# MDR32F8 register map
Vendor: Milandr; File version: 1.0
CPU: CM4 r1p1, little endian, no MPU, no FPU, 3 interrupt priority bits
Registers are 32-bit, read-write, reset 0x0 unless marked. A register's access mark holds for its fields unless they carry their own. Offsets are from the block's base; [hi:lo] are bit positions; {n}, {i} and the like mark numbered series; 'fields as' and 'values as' point back to an identical list.

## ARINC429T — ARINC429 Transive Controller
Base 0x400A0000
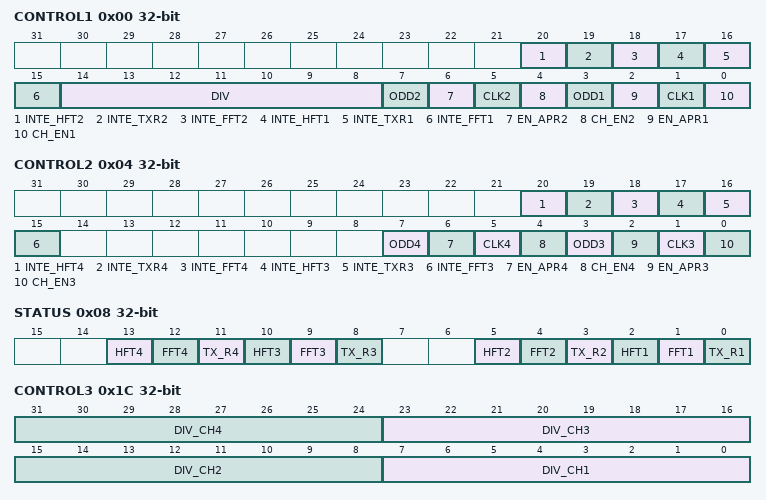
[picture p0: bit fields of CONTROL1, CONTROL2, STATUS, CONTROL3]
0x00 CONTROL1
  [20] INTE_HFT2, [19] INTE_TXR2, [18] INTE_FFT2, [17] INTE_HFT1, [16] INTE_TXR1, [15] INTE_FFT1, [14:8] DIV, [7] ODD2, [6] EN_APR2, [5] CLK2, [4] CH_EN2, [3] ODD1, [2] EN_APR1, [1] CLK1, [0] CH_EN1
0x04 CONTROL2
  [20] INTE_HFT4, [19] INTE_TXR4, [18] INTE_FFT4, [17] INTE_HFT3, [16] INTE_TXR3, [15] INTE_FFT3, [7] ODD4, [6] EN_APR4, [5] CLK4, [4] CH_EN4, [3] ODD3, [2] EN_APR3, [1] CLK3, [0] CH_EN3
0x08 STATUS
  [13] HFT4, [12] FFT4, [11] TX_R4, [10] HFT3, [9] FFT3, [8] TX_R3, [5] HFT2, [4] FFT2, [3] TX_R2, [2] HFT1, [1] FFT1, [0] TX_R1
{0x8+4i} DATA{i}_T wo (i=1..4)
0x1C CONTROL3
  [8n-1:8n-8] DIV_CH{n} (n=1..4)
0x20 CONTROL4
  [3:0] ENSYNC

## MDR_MILDAT_15530 — MIL_DATA
Base 0x400A6000
Same registers: MDR_MILDAT_15531 0x400A8000

## MDR_MIL_STD_15530 — MIL_STD_1553 interfase controller registers
Base 0x400A7000
Same registers: MDR_MIL_STD_15531 0x400A9000
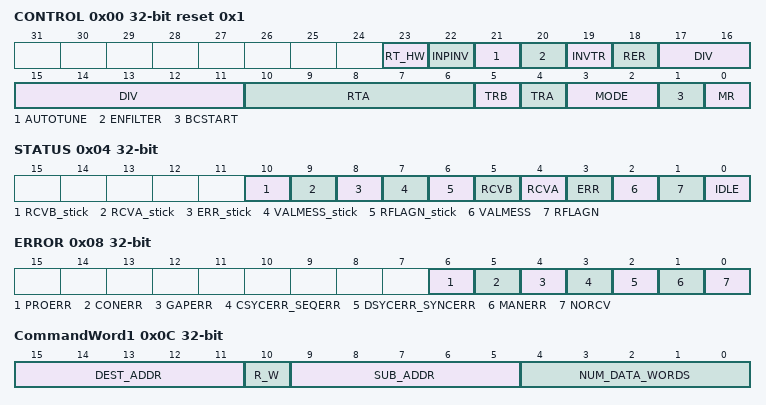
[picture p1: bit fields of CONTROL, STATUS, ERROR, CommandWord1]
0x00 CONTROL reset 0x1 — MIL_STD_1553 Register control
  [23] RT_HW, [22] INPINV, [21] AUTOTUNE, [20] ENFILTER, [19] INVTR, [18] RER, [17:11] DIV, [10:6] RTA, [5] TRB, [4] TRA, [3:2] MODE, [1] BCSTART, [0] MR
0x04 STATUS ro — MIL_STD_1553 Register status
  [10] RCVB_stick, [9] RCVA_stick, [8] ERR_stick, [7] VALMESS_stick, [6] RFLAGN_stick, [5] RCVB, [4] RCVA, [3] ERR, [2] VALMESS, [1] RFLAGN, [0] IDLE
0x08 ERROR ro — MIL_STD_1553 Register error
  [6] PROERR, [5] CONERR, [4] GAPERR, [3] CSYCERR_SEQERR, [2] DSYCERR_SYNCERR, [1] MANERR, [0] NORCV
0x0C CommandWord1 — MIL_STD_1553 Register Command Word 1
  [15:11] DEST_ADDR, [10] R_W, [9:5] SUB_ADDR, [4:0] NUM_DATA_WORDS
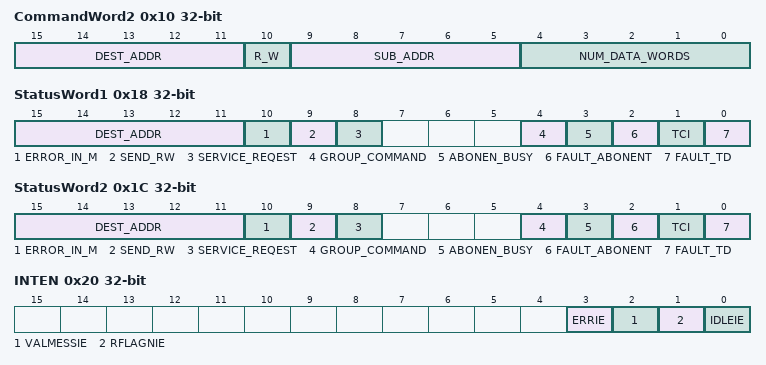
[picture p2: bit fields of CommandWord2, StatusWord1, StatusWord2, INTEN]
0x10 CommandWord2 — MIL_STD_1553 Register Command Word 2
  [15:11] DEST_ADDR, [10] R_W, [9:5] SUB_ADDR, [4:0] NUM_DATA_WORDS
0x14 MODE_DATA — MIL_STD_1553 Register Mode Data
  [15:0] MODE_DATA
0x18 StatusWord1 — MIL_STD_1553 Register Status Word 1
  [15:11] DEST_ADDR, [10] ERROR_IN_M, [9] SEND_RW, [8] SERVICE_REQEST, [4] GROUP_COMMAND, [3] ABONEN_BUSY, [2] FAULT_ABONENT, [1] TCI, [0] FAULT_TD
0x1C StatusWord2 — MIL_STD_1553 Register Status Word 2
  fields as StatusWord1
0x20 INTEN — MIL_STD_1553
  [3] ERRIE, [2] VALMESSIE, [1] RFLAGNIE, [0] IDLEIE
0x24 MSG ro — MIL_STD_1553
  [13:0] MESSAGE_CODE

## ADC0 — ADC
Base 0x400AA000
Same registers: ADC1 0x400AB000
0x00 KEY — Key lock Register
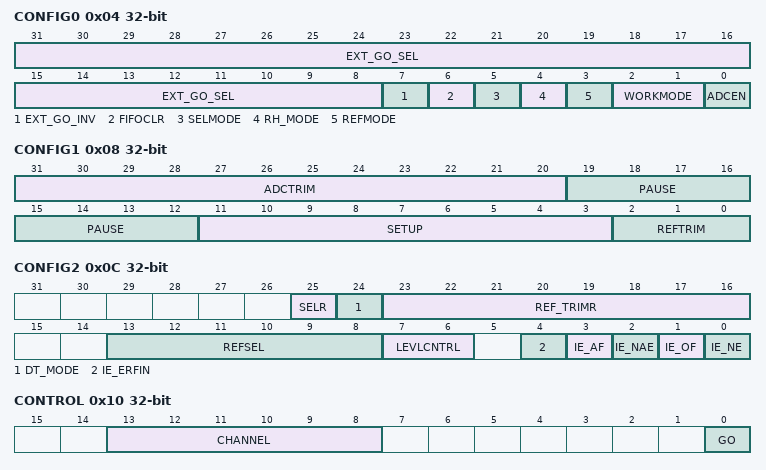
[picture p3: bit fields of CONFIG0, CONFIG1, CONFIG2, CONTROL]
0x04 CONFIG0 — ADC Configuration0 Register
  [31:8] EXT_GO_SEL, [7] EXT_GO_INV, [6] FIFOCLR, [5] SELMODE, [4] RH_MODE, [3] REFMODE, [2:1] WORKMODE, [0] ADCEN
0x08 CONFIG1 — ADC Configuration1 Register
  [31:20] ADCTRIM, [19:12] PAUSE, [11:3] SETUP, [2:0] REFTRIM
0x0C CONFIG2 — ADC Configuration Register
  [25] SELR, [24] DT_MODE, [23:16] REF_TRIMR, [13:8] REFSEL, [7:6] LEVLCNTRL, [4] IE_ERFIN, [3] IE_AF, [2] IE_NAE, [1] IE_OF, [0] IE_NE
0x10 CONTROL — ADC Control Register
  [13:8] CHANNEL, [0] GO
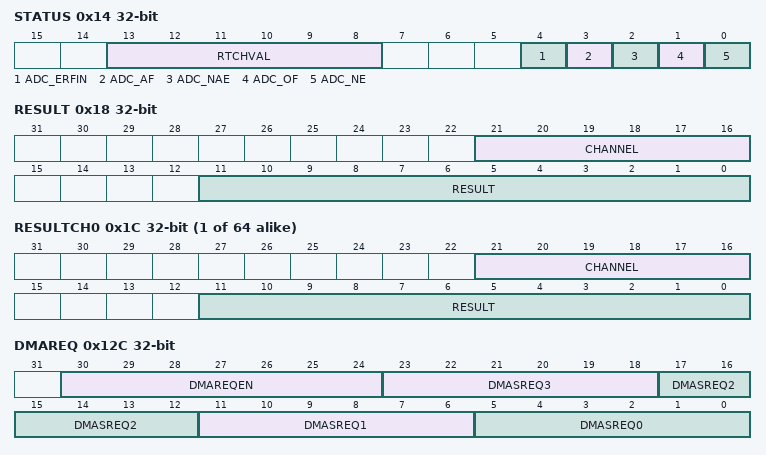
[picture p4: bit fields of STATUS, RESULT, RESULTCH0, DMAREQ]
0x14 STATUS ro — ADC Status Register
  [13:8] RTCHVAL, [4] ADC_ERFIN, [3] ADC_AF, [2] ADC_NAE, [1] ADC_OF, [0] ADC_NE
0x18 RESULT ro — ADC Result Register
  [21:16] CHANNEL, [11:0] RESULT
{0x1C+4i} RESULTCH{i} ro (i=0..63) — ADC Result Register
  [21:16] CHANNEL, [11:0] RESULT
0x11C MAX_LEVEL — ADC MAC Level Register
  [11:0] MAX_LEVEL
0x120 MIN_LEVEL — ADC MIN Level Register
  [11:0] MIN_LEVEL
0x124 CHSEL0 (reset mask 0xFFFFFFF) — Selec Channel Register
  [31:0] CHSEL
0x128 CHSEL1 (reset mask 0xFFFFFFF) — Selec Channel Register
  [31:0] CHSEL
0x12C DMAREQ — DMA Request Register
  [30:24] DMAREQEN, [6n+5:6n] DMASREQ{n} (n=0..3)
0x130 STATRCH0 ro — ADC STAT Register
  [30:0] STRCH
0x134 STATRCH1 ro — ADC STAT Register
  [30:0] STRCH
0x138 FIFOEN0 — ADC FIFO write Enable
  [31:0] FIFOEN
0x13C FIFOEN1 — ADC FIFO write Enable
  [31:0] FIFOEN

## DAC0 — DAC
Base 0x400AC000
Same registers: DAC1 0x400AD000
0x00 KEY — Key lock Register
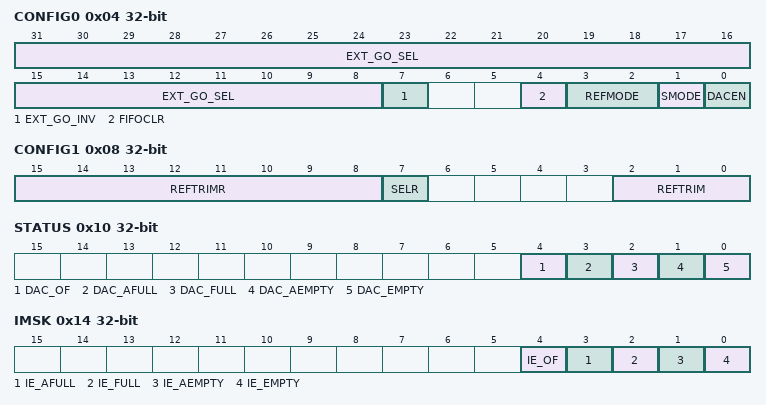
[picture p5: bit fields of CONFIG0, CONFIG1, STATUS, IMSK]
0x04 CONFIG0 — DAC Configuration Register
  [31:8] EXT_GO_SEL, [7] EXT_GO_INV, [4] FIFOCLR, [3:2] REFMODE, [1] SMODE, [0] DACEN
0x08 CONFIG1 — DAC Configuration Register
  [15:8] REFTRIMR, [7] SELR, [2:0] REFTRIM
0x0C DATA — DAC Data Register
  [11:0] DATA
0x10 STATUS ro — DAC Status Register
  [4] DAC_OF rw, [3] DAC_AFULL, [2] DAC_FULL, [1] DAC_AEMPTY, [0] DAC_EMPTY
0x14 IMSK — DAC inerrupt Register
  [4] IE_OF, [3] IE_AFULL, [2] IE_FULL, [1] IE_AEMPTY, [0] IE_EMPTY
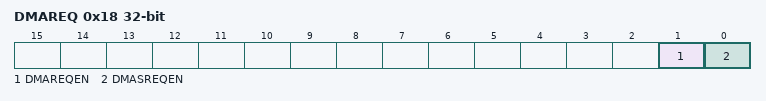
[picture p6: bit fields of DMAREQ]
0x18 DMAREQ — DAC DMA Request Register
  [1] DMAREQEN, [0] DMASREQEN

## MDR_ETH — Ethernet
Base 0x21000000
0x00 DELIMITER 16-bit reset 0x1000
  [15:0] Delimeter
0x02 MAC_T 16-bit reset 0x78AB
0x04 MAC_M 16-bit reset 0x3456
0x06 MAC_H 16-bit reset 0x12
{0x8+2i} HASH{i} 16-bit (i=0..2)
  [15:0] HASH
0x0E HASH3 16-bit reset 0x8000
  [15:0] HASH
0x10 IPG 16-bit reset 0x60
0x12 PSC 16-bit reset 0x50
0x14 BAG 16-bit reset 0x200
0x16 JITTERWND 16-bit reset 0x5
  [15:0] JWND
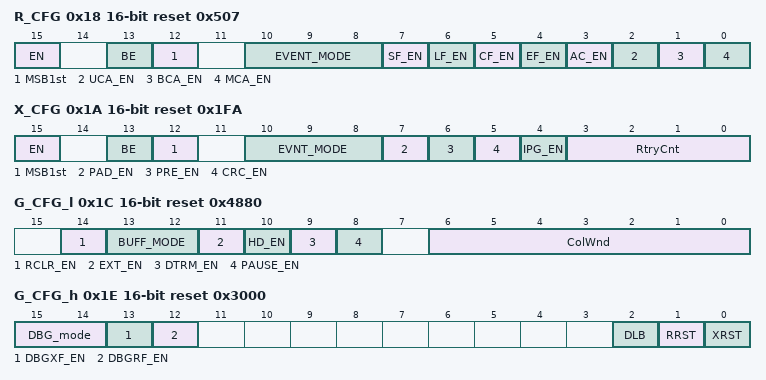
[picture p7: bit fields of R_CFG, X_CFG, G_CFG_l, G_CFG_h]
0x18 R_CFG 16-bit reset 0x507
  [15] EN, [13] BE, [12] MSB1st, [10:8] EVENT_MODE, [7] SF_EN, [6] LF_EN, [5] CF_EN, [4] EF_EN, [3] AC_EN, [2] UCA_EN, [1] BCA_EN, [0] MCA_EN
0x1A X_CFG 16-bit reset 0x1FA
  [15] EN, [13] BE, [12] MSB1st, [10:8] EVNT_MODE, [7] PAD_EN, [6] PRE_EN, [5] CRC_EN, [4] IPG_EN, [3:0] RtryCnt
0x1C G_CFG_l 16-bit reset 0x4880
  [14] RCLR_EN, [13:12] BUFF_MODE, [11] EXT_EN, [10] HD_EN, [9] DTRM_EN, [8] PAUSE_EN, [6:0] ColWnd
0x1E G_CFG_h 16-bit reset 0x3000
  [15:14] DBG_mode, [13] DBGXF_EN, [12] DBGRF_EN, [2] DLB, [1] RRST, [0] XRST
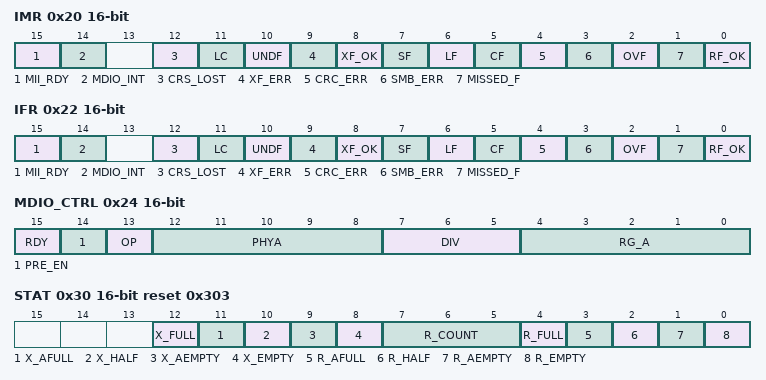
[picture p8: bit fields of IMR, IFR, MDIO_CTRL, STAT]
0x20 IMR 16-bit
  [15] MII_RDY, [14] MDIO_INT, [12] CRS_LOST, [11] LC, [10] UNDF, [9] XF_ERR, [8] XF_OK, [7] SF, [6] LF, [5] CF, [4] CRC_ERR, [3] SMB_ERR, [2] OVF, [1] MISSED_F, [0] RF_OK
0x22 IFR 16-bit
  fields as IMR
0x24 MDIO_CTRL 16-bit
  [15] RDY, [14] PRE_EN, [13] OP, [12:8] PHYA, [7:5] DIV, [4:0] RG_A
0x26 MDIO 16-bit
  [15:0] DATA
0x28 R_Head 16-bit
  [15:0] RHead
0x2A X_Tail 16-bit reset 0x1000
  [15:0] XTail
0x2C R_Tail 16-bit ro
  [15:0] RTail
0x2E X_Head 16-bit ro reset 0x1000
  [15:0] XHead
0x30 STAT 16-bit ro reset 0x303
  [12] X_FULL, [11] X_AFULL, [10] X_HALF, [9] X_AEMPTY, [8] X_EMPTY, [7:5] R_COUNT, [4] R_FULL, [3] R_AFULL, [2] R_HALF, [1] R_AEMPTY, [0] R_EMPTY
0x32 RCOUNTER ro
  [15:0] CNT
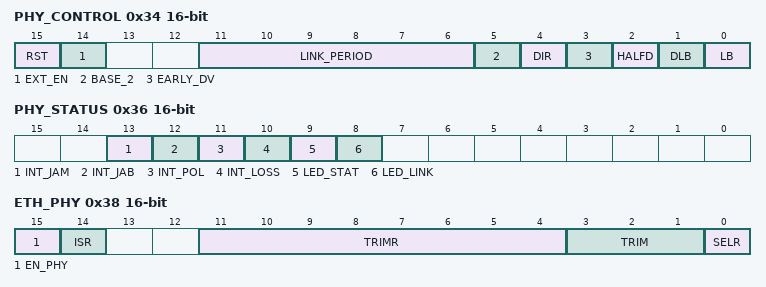
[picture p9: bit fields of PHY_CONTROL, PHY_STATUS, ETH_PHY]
0x34 PHY_CONTROL 16-bit
  [15] RST, [14] EXT_EN, [11:6] LINK_PERIOD, [5] BASE_2, [4] DIR, [3] EARLY_DV, [2] HALFD, [1] DLB, [0] LB
0x36 PHY_STATUS 16-bit ro
  [13] INT_JAM, [12] INT_JAB, [11] INT_POL, [10] INT_LOSS, [9] LED_STAT, [8] LED_LINK
0x38 ETH_PHY 16-bit
  [15] EN_PHY, [14] ISR, [11:4] TRIMR, [3:1] TRIM, [0] SELR

## MDR_DMA — DMA controller registers
Base 0xE0042000
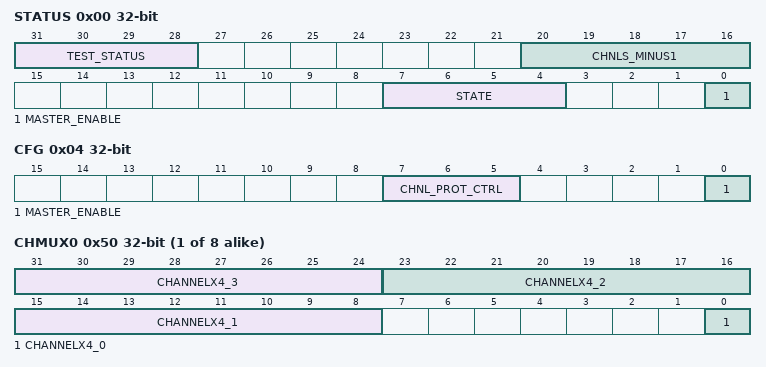
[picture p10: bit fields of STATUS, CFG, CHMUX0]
0x00 STATUS ro — DMA Status Register
  [31:28] TEST_STATUS, [20:16] CHNLS_MINUS1, [7:4] STATE, [0] MASTER_ENABLE
0x04 CFG wo — DMA Configuration Register
  [7:5] CHNL_PROT_CTRL, [0] MASTER_ENABLE
0x08 CTRL_BASE_PTR
  [31:10] CTRL_BASE_PTR
0x0C ALT_CTRL_BASE_PTR ro
0x10 WAITONREQ_STATUS ro
0x14 CHNL_SW_REQUEST wo
0x18 CHNL_USEBURST_SET
0x1C CHNL_USEBURST_CLR wo
0x20 CHNL_REQ_MASK_SET
0x24 CHNL_REQ_MASK_CLR wo
0x28 CHNL_ENABLE_SET
0x2C CHNL_ENABLE_CLR wo
0x30 CHNL_PRI_ALT_SET
0x34 CHNL_PRI_ALT_CLR wo
0x38 CHNL_PRIORITY_SET
0x3C CHNL_PRIORITY_CLR wo
0x4C ERR_CLR
  [0] ERR_CLR
{0x50+4i} CHMUX{i} (i=0..7)
  [31:24] CHANNELX4_3, [23:16] CHANNELX4_2, [15:8] CHANNELX4_1, [0] CHANNELX4_0
